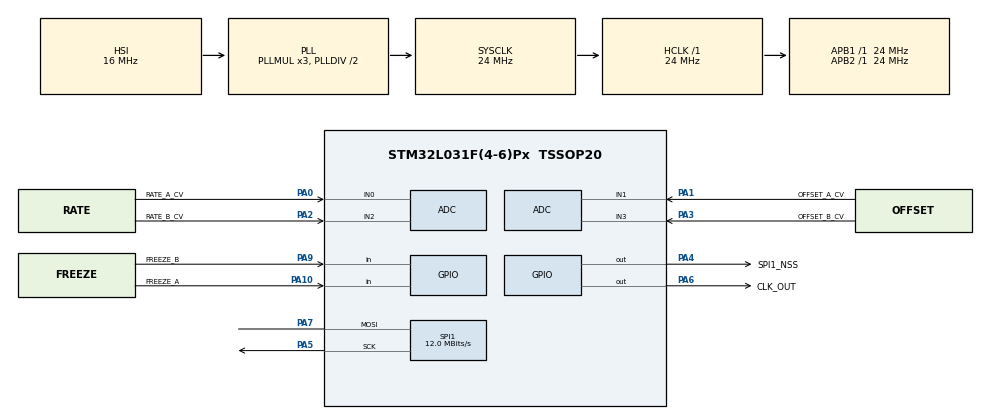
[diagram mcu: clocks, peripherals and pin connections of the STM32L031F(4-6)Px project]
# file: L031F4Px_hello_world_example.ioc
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ADC.ContinuousConvMode=ENABLE
ADC.DMAContinuousRequests=ENABLE
ADC.ExternalTrigConv=ADC_SOFTWARE_START
ADC.Overrun=ADC_OVR_DATA_OVERWRITTEN
ADC.SamplingTime=ADC_SAMPLETIME_160CYCLES_5
Dma.ADC.0.Direction=DMA_PERIPH_TO_MEMORY
Dma.ADC.0.Instance=DMA1_Channel1
Dma.ADC.0.MemDataAlignment=DMA_MDATAALIGN_WORD
Dma.ADC.0.MemInc=DMA_MINC_ENABLE
Dma.ADC.0.Mode=DMA_CIRCULAR
Dma.ADC.0.PeriphDataAlignment=DMA_PDATAALIGN_WORD
Dma.ADC.0.PeriphInc=DMA_PINC_DISABLE
Dma.ADC.0.Priority=DMA_PRIORITY_LOW
Dma.Request0=ADC
Mcu.Family=STM32L0
Mcu.Name=STM32L031F(4-6)Px
Mcu.Package=TSSOP20
NVIC.DMA1_Channel1_IRQn=true\:0\:0\:false\:false\:true\:false\:true\:true
PA0-CK_IN.GPIO_Label=RATE_A_CV
PA0-CK_IN.Mode=IN0
PA0-CK_IN.Signal=ADC_IN0
PA1.GPIO_Label=OFFSET_A_CV
PA1.Mode=IN1
PA1.Signal=ADC_IN1
PA10.GPIO_Label=FREEZE_A
PA10.GPIO_PuPd=GPIO_PULLDOWN
PA10.Signal=GPIO_Input
PA13.Mode=Serial_Wire
PA13.Signal=SYS_SWDIO
PA14.Mode=Serial_Wire
PA14.Signal=SYS_SWCLK
PA2.GPIO_Label=RATE_B_CV
PA2.Mode=IN2
PA2.Signal=ADC_IN2
PA3.GPIO_Label=OFFSET_B_CV
PA3.Mode=IN3
PA3.Signal=ADC_IN3
PA4.GPIO_Label=SPI1_NSS
PA4.PinState=GPIO_PIN_SET
PA4.Signal=GPIO_Output
PA5.Mode=Simplex_Bidirectional_Master
PA5.Signal=SPI1_SCK
PA6.GPIO_Label=CLK_OUT
PA6.Signal=GPIO_Output
PA7.Mode=Simplex_Bidirectional_Master
PA7.Signal=SPI1_MOSI
PA9.GPIO_Label=FREEZE_B
PA9.GPIO_PuPd=GPIO_PULLDOWN
PA9.Signal=GPIO_Input
ProjectManager.HeapSize=0x200
ProjectManager.StackSize=0x400
ProjectManager.TargetToolchain=STM32CubeIDE
RCC.AHBFreq_Value=24000000
RCC.APB1Freq_Value=24000000
RCC.APB1TimFreq_Value=24000000
RCC.APB2Freq_Value=24000000
RCC.APB2TimFreq_Value=24000000
RCC.HCLKFreq_Value=24000000
RCC.HSE_VALUE=8000000
RCC.HSI16_VALUE=16000000
RCC.HSI_VALUE=16000000
RCC.LSE_VALUE=32768
RCC.MSI_VALUE=2097000
RCC.SYSCLKFreq_VALUE=24000000
RCC.SYSCLKSource=RCC_SYSCLKSOURCE_PLLCLK
RCC.VCOOutputFreq_Value=48000000
SPI1.BaudRatePrescaler=SPI_BAUDRATEPRESCALER_2
SPI1.CalculateBaudRate=12.0 MBits/s
SPI1.DataSize=SPI_DATASIZE_16BIT
SPI1.Direction=SPI_DIRECTION_1LINE
SPI1.Mode=SPI_MODE_MASTER
SPI1.VirtualType=VM_MASTER
board=custom

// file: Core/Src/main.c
/* USER CODE BEGIN Header */
/**
  ******************************************************************************
  * @file           : main.c
  * @brief          : Main program body
  ******************************************************************************
  * @attention
  *
  * Copyright (c) 2024 STMicroelectronics.
  * All rights reserved.
  *
  * This software is licensed under terms that can be found in the LICENSE file
  * in the root directory of this software component.
  * If no LICENSE file comes with this software, it is provided AS-IS.
  *
  ******************************************************************************
  */
/* USER CODE END Header */
#include "main.h"
#include "adc.h"
#include "dma.h"
#include "spi.h"
#include "gpio.h"

/* USER CODE BEGIN Includes */

#include <app_main.hpp>

/* USER CODE END Includes */

void SystemClock_Config(void);

int main(void)
{

  /* MCU Configuration--------------------------------------------------------*/

  /* Reset of all peripherals, Initializes the Flash interface and the Systick. */
  HAL_Init();

  /* Configure the system clock */
  SystemClock_Config();

  /* Initialize all configured peripherals */
  MX_GPIO_Init();
  MX_DMA_Init();
  MX_ADC_Init();
  MX_SPI1_Init();
  /* USER CODE BEGIN 2 */

  // application main function enters an infinite loop an does not return
  app_main();

  /* USER CODE END 2 */

  /* Infinite loop */
  /* USER CODE BEGIN WHILE */
  // never reached
  while (1)
  {
    /* USER CODE END WHILE */

  }
}

void SystemClock_Config(void)
{
  RCC_OscInitTypeDef RCC_OscInitStruct = {0};
  RCC_ClkInitTypeDef RCC_ClkInitStruct = {0};

  /** Configure the main internal regulator output voltage
  */
  __HAL_PWR_VOLTAGESCALING_CONFIG(PWR_REGULATOR_VOLTAGE_SCALE1);

  /** Initializes the RCC Oscillators according to the specified parameters
  * in the RCC_OscInitTypeDef structure.
  */
  RCC_OscInitStruct.OscillatorType = RCC_OSCILLATORTYPE_HSI;
  RCC_OscInitStruct.HSIState = RCC_HSI_ON;
  RCC_OscInitStruct.HSICalibrationValue = RCC_HSICALIBRATION_DEFAULT;
  RCC_OscInitStruct.PLL.PLLState = RCC_PLL_ON;
  RCC_OscInitStruct.PLL.PLLSource = RCC_PLLSOURCE_HSI;
  RCC_OscInitStruct.PLL.PLLMUL = RCC_PLLMUL_3;
  RCC_OscInitStruct.PLL.PLLDIV = RCC_PLLDIV_2;
  if (HAL_RCC_OscConfig(&RCC_OscInitStruct) != HAL_OK)
  {
    Error_Handler();
  }

  /** Initializes the CPU, AHB and APB buses clocks
  */
  RCC_ClkInitStruct.ClockType = RCC_CLOCKTYPE_HCLK|RCC_CLOCKTYPE_SYSCLK
                              |RCC_CLOCKTYPE_PCLK1|RCC_CLOCKTYPE_PCLK2;
  RCC_ClkInitStruct.SYSCLKSource = RCC_SYSCLKSOURCE_PLLCLK;
  RCC_ClkInitStruct.AHBCLKDivider = RCC_SYSCLK_DIV1;
  RCC_ClkInitStruct.APB1CLKDivider = RCC_HCLK_DIV1;
  RCC_ClkInitStruct.APB2CLKDivider = RCC_HCLK_DIV1;

  if (HAL_RCC_ClockConfig(&RCC_ClkInitStruct, FLASH_LATENCY_1) != HAL_OK)
  {
    Error_Handler();
  }
}

void Error_Handler(void)
{
  __disable_irq();
  while (1)
  {
  }
}
